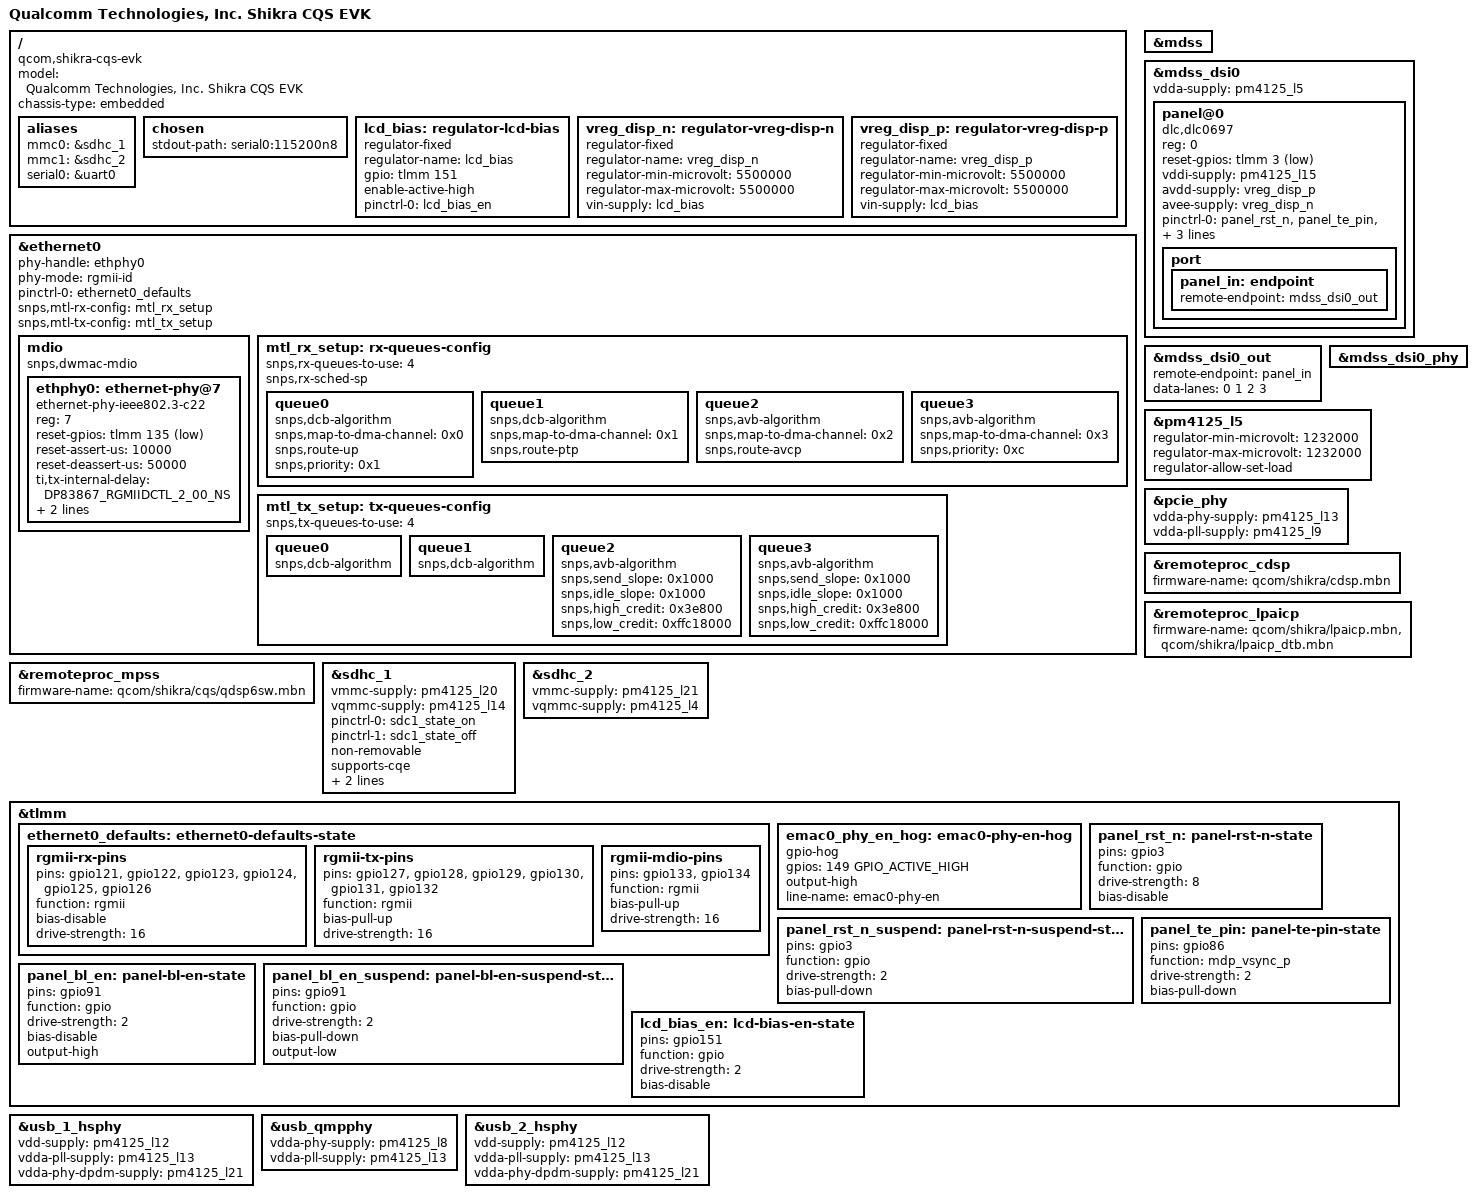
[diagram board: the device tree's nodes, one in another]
// SPDX-License-Identifier: BSD-3-Clause
/*
 * Copyright (c) Qualcomm Technologies, Inc. and/or its subsidiaries.
 */

/dts-v1/;

#include "shikra-cqm-som.dtsi"
#include "shikra-evk.dtsi"
#include <dt-bindings/gpio/gpio.h>
#include <dt-bindings/net/ti-dp83867.h>

/ {
	model = "Qualcomm Technologies, Inc. Shikra CQS EVK";
	compatible = "qcom,shikra-cqs-evk", "qcom,shikra-cqs-som", "qcom,shikra";
	chassis-type = "embedded";

	aliases {
		mmc0 = &sdhc_1;
		mmc1 = &sdhc_2; /* SDC2 SD card slot */
		serial0 = &uart0;
	};

	chosen {
		stdout-path = "serial0:115200n8";
	};

	lcd_bias: regulator-lcd-bias {
		compatible = "regulator-fixed";
		regulator-name = "lcd_bias";
		gpio = <&tlmm 151 GPIO_ACTIVE_HIGH>;
		enable-active-high;
		pinctrl-0 = <&lcd_bias_en>;
		pinctrl-names = "default";
	};

	vreg_disp_n: regulator-vreg-disp-n {
		compatible = "regulator-fixed";
		regulator-name = "vreg_disp_n";
		regulator-min-microvolt = <5500000>;
		regulator-max-microvolt = <5500000>;
		vin-supply = <&lcd_bias>;
	};

	vreg_disp_p: regulator-vreg-disp-p {
		compatible = "regulator-fixed";
		regulator-name = "vreg_disp_p";
		regulator-min-microvolt = <5500000>;
		regulator-max-microvolt = <5500000>;
		vin-supply = <&lcd_bias>;
	};
};

&ethernet0 {
	status = "okay";
	phy-handle = <&ethphy0>;
	phy-mode = "rgmii-id";

	pinctrl-names = "default";
	pinctrl-0 = <&ethernet0_defaults>;

	snps,mtl-rx-config = <&mtl_rx_setup>;
	snps,mtl-tx-config = <&mtl_tx_setup>;

	mdio {
		compatible = "snps,dwmac-mdio";
		#address-cells = <1>;
		#size-cells = <0>;

		ethphy0: ethernet-phy@7 {
			compatible = "ethernet-phy-ieee802.3-c22";
			reg = <7>;
			reset-gpios = <&tlmm 135 GPIO_ACTIVE_LOW>;
			reset-assert-us = <10000>;
			reset-deassert-us = <50000>;
			ti,tx-internal-delay = <DP83867_RGMIIDCTL_2_00_NS>;
			ti,rx-internal-delay = <DP83867_RGMIIDCTL_2_00_NS>;
		};
	};

	mtl_rx_setup: rx-queues-config {
		snps,rx-queues-to-use = <4>;
		snps,rx-sched-sp;

		queue0 {
			snps,dcb-algorithm;
			snps,map-to-dma-channel = <0x0>;
			snps,route-up;
			snps,priority = <0x1>;
		};

		queue1 {
			snps,dcb-algorithm;
			snps,map-to-dma-channel = <0x1>;
			snps,route-ptp;
		};

		queue2 {
			snps,avb-algorithm;
			snps,map-to-dma-channel = <0x2>;
			snps,route-avcp;
		};

		queue3 {
			snps,avb-algorithm;
			snps,map-to-dma-channel = <0x3>;
			snps,priority = <0xc>;
		};
	};

	mtl_tx_setup: tx-queues-config {
		snps,tx-queues-to-use = <4>;

		queue0 {
			snps,dcb-algorithm;
		};

		queue1 {
			snps,dcb-algorithm;
		};

		queue2 {
			snps,avb-algorithm;
			snps,send_slope = <0x1000>;
			snps,idle_slope = <0x1000>;
			snps,high_credit = <0x3e800>;
			snps,low_credit = <0xffc18000>;
		};

		queue3 {
			snps,avb-algorithm;
			snps,send_slope = <0x1000>;
			snps,idle_slope = <0x1000>;
			snps,high_credit = <0x3e800>;
			snps,low_credit = <0xffc18000>;
		};
	};
};

&mdss {
	status = "okay";
};

&mdss_dsi0 {
	vdda-supply = <&pm4125_l5>;

	status = "okay";

	panel@0 {
		compatible = "dlc,dlc0697", "ilitek,ili7807s";
		reg = <0>;

		reset-gpios = <&tlmm 3 GPIO_ACTIVE_LOW>;

		vddi-supply = <&pm4125_l15>;
		avdd-supply = <&vreg_disp_p>;
		avee-supply = <&vreg_disp_n>;

		pinctrl-0 = <&panel_rst_n &panel_te_pin &panel_bl_en>;
		pinctrl-1 = <&panel_rst_n_suspend &panel_bl_en_suspend>;
		pinctrl-names = "default", "sleep";

		port {
			panel_in: endpoint {
				remote-endpoint = <&mdss_dsi0_out>;
			};
		};
	};
};

&mdss_dsi0_out {
	remote-endpoint = <&panel_in>;
	data-lanes = <0 1 2 3>;
};

&mdss_dsi0_phy {
	status = "okay";
};

&pm4125_l5 {
	/* DSI VDDA - must be at NOM voltage for PHY PLL lock */
	regulator-min-microvolt = <1232000>;
	regulator-max-microvolt = <1232000>;
	regulator-allow-set-load;
};

&pcie_phy {
	vdda-phy-supply = <&pm4125_l13>;
	vdda-pll-supply = <&pm4125_l9>;

	status = "okay";
};

&remoteproc_cdsp {
	firmware-name = "qcom/shikra/cdsp.mbn";

	status = "okay";
};

&remoteproc_lpaicp {
	firmware-name = "qcom/shikra/lpaicp.mbn",
			"qcom/shikra/lpaicp_dtb.mbn";

	status = "okay";
};

&remoteproc_mpss {
	firmware-name = "qcom/shikra/cqs/qdsp6sw.mbn";

	status = "okay";
};

&sdhc_1 {
	vmmc-supply = <&pm4125_l20>;
	vqmmc-supply = <&pm4125_l14>;

	pinctrl-0 = <&sdc1_state_on>;
	pinctrl-1 = <&sdc1_state_off>;
	pinctrl-names = "default", "sleep";

	non-removable;
	supports-cqe;
	no-sdio;
	no-sd;

	status = "okay";
};

&sdhc_2 {
	vmmc-supply = <&pm4125_l21>;
	vqmmc-supply = <&pm4125_l4>;

	status = "okay";
};

&tlmm {
	ethernet0_defaults: ethernet0-defaults-state {
		rgmii-rx-pins {
			pins = "gpio121", "gpio122", "gpio123",
			       "gpio124", "gpio125", "gpio126";
			function = "rgmii";
			bias-disable;
			drive-strength = <16>;
		};
		rgmii-tx-pins {
			pins = "gpio127", "gpio128", "gpio129",
			       "gpio130", "gpio131", "gpio132";
			function = "rgmii";
			bias-pull-up;
			drive-strength = <16>;
		};
		rgmii-mdio-pins {
			pins = "gpio133", "gpio134";
			function = "rgmii";
			bias-pull-up;
			drive-strength = <16>;
		};
	};

	emac0_phy_en_hog: emac0-phy-en-hog {
		gpio-hog;
		gpios = <149 GPIO_ACTIVE_HIGH>;
		output-high;
		line-name = "emac0-phy-en";
	};

	panel_rst_n: panel-rst-n-state {
		pins = "gpio3";
		function = "gpio";
		drive-strength = <8>;
		bias-disable;
	};

	panel_rst_n_suspend: panel-rst-n-suspend-state {
		pins = "gpio3";
		function = "gpio";
		drive-strength = <2>;
		bias-pull-down;
	};

	panel_te_pin: panel-te-pin-state {
		pins = "gpio86";
		function = "mdp_vsync_p";
		drive-strength = <2>;
		bias-pull-down;
	};

	panel_bl_en: panel-bl-en-state {
		pins = "gpio91";
		function = "gpio";
		drive-strength = <2>;
		bias-disable;
		output-high;
	};

	panel_bl_en_suspend: panel-bl-en-suspend-state {
		pins = "gpio91";
		function = "gpio";
		drive-strength = <2>;
		bias-pull-down;
		output-low;
	};

	lcd_bias_en: lcd-bias-en-state {
		pins = "gpio151";
		function = "gpio";
		drive-strength = <2>;
		bias-disable;
	};
};

&usb_1_hsphy {
	vdd-supply = <&pm4125_l12>;
	vdda-pll-supply = <&pm4125_l13>;
	vdda-phy-dpdm-supply = <&pm4125_l21>;

	status = "okay";
};

&usb_qmpphy {
	vdda-phy-supply = <&pm4125_l8>;
	vdda-pll-supply = <&pm4125_l13>;

	status = "okay";
};

&usb_2_hsphy {
	vdd-supply = <&pm4125_l12>;
	vdda-pll-supply = <&pm4125_l13>;
	vdda-phy-dpdm-supply = <&pm4125_l21>;

	status = "okay";
};
